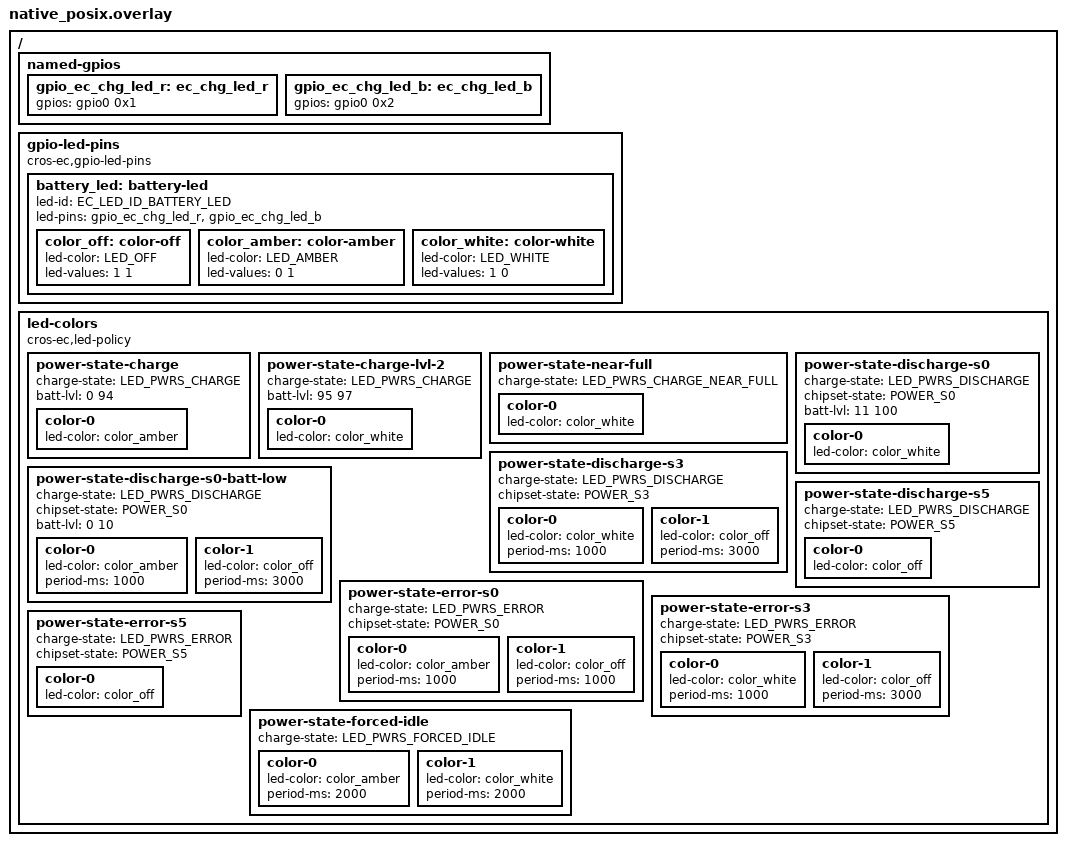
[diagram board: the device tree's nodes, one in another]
/* Copyright 2023 The ChromiumOS Authors
 * Use of this source code is governed by a BSD-style license that can be
 * found in the LICENSE file.
 */

#include <board-overlays/native_posix.dts>

/ {
	named-gpios {
                gpio_ec_chg_led_r: ec_chg_led_r {
                        gpios = < &gpio0 0x1 0x60000 >;
                };
                gpio_ec_chg_led_b: ec_chg_led_b {
                        gpios = < &gpio0 0x2 0x60000 >;
                };

	};

	gpio-led-pins {
		compatible = "cros-ec,gpio-led-pins";

		battery_led: battery-led {
			led-id = "EC_LED_ID_BATTERY_LED";
			led-pins = <&gpio_ec_chg_led_r &gpio_ec_chg_led_b>;

			color_off: color-off {
				led-color = "LED_OFF";
				led-values = <1 1>;
			};

			color_amber: color-amber {
				led-color = "LED_AMBER";
				led-values = <0 1>;
			};

			color_white: color-white {
				led-color = "LED_WHITE";
				led-values = <1 0>;
			};
		};
	};

	led-colors {
		compatible = "cros-ec,led-policy";

		power-state-charge {
			charge-state = "LED_PWRS_CHARGE";
			/* Battery percent range (>= Empty, <= 94%) */
			batt-lvl = <0 94>;

			color-0 {
				led-color = <&color_amber>;
			};
		};

		// Note - this purposely causes an LED policy gap to verify
		// that led_policy.default can detect gaps.
		power-state-charge-lvl-2 {
			charge-state = "LED_PWRS_CHARGE";
			/* Battery percent range (>= 95%, <= Near Full) */
			batt-lvl = <95 97>;

			color-0 {
				led-color = <&color_white>;
			};
		};

		power-state-near-full {
			charge-state = "LED_PWRS_CHARGE_NEAR_FULL";

			color-0 {
				led-color = <&color_white>;
			};
		};

		power-state-discharge-s0 {
			charge-state = "LED_PWRS_DISCHARGE";
			chipset-state = "POWER_S0";
			/* Battery percent range (>= 11%, <= Full) */
			batt-lvl = <11 100>;

			color-0 {
				led-color = <&color_white>;
			};
		};

		power-state-discharge-s0-batt-low {
			charge-state = "LED_PWRS_DISCHARGE";
			chipset-state = "POWER_S0";
			/* Battery percent range (>= Empty, <= 10%) */
			batt-lvl = <0 10>;

			/* Amber 1 sec, off 3 sec */
			color-0 {
				led-color = <&color_amber>;
				period-ms = <1000>;
			};
			color-1 {
				led-color = <&color_off>;
				period-ms = <3000>;
			};
		};

		power-state-discharge-s3 {
			charge-state = "LED_PWRS_DISCHARGE";
			chipset-state = "POWER_S3";

			/* White 1 sec, off 3 sec */
			color-0 {
				led-color = <&color_white>;
				period-ms = <1000>;
			};
			color-1 {
				led-color = <&color_off>;
				period-ms = <3000>;
			};
		};

		power-state-discharge-s5 {
			charge-state = "LED_PWRS_DISCHARGE";
			chipset-state = "POWER_S5";

			color-0 {
				led-color = <&color_off>;
			};
		};

		power-state-error-s0 {
			charge-state = "LED_PWRS_ERROR";
			chipset-state = "POWER_S0";
			/* Amber 1 sec, off 1 sec */
			color-0 {
				led-color = <&color_amber>;
				period-ms = <1000>;
			};
			color-1 {
				led-color = <&color_off>;
				period-ms = <1000>;
			};
		};

		power-state-error-s3 {
			charge-state = "LED_PWRS_ERROR";
			chipset-state = "POWER_S3";
			/* White 1 sec, off 3 sec */
			color-0 {
				led-color = <&color_white>;
				period-ms = <1000>;
			};
			color-1 {
				led-color = <&color_off>;
				period-ms = <3000>;
			};
		};

		power-state-error-s5 {
			charge-state = "LED_PWRS_ERROR";
			chipset-state = "POWER_S5";

			color-0 {
				led-color = <&color_off>;
			};
		};

		power-state-forced-idle {
			charge-state = "LED_PWRS_FORCED_IDLE";

			/* Amber 2 sec, White 2 sec */
			color-0 {
				led-color = <&color_amber>;
				period-ms = <2000>;
			};
			color-1 {
				led-color = <&color_white>;
				period-ms = <2000>;
			};
		};
	};
};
